# WBZ351 register map
Vendor: Microchip
Registers are 32-bit, read-write, reset 0x0 unless marked. A register's access mark holds for its fields unless they carry their own. Addresses are absolute, and some are shared; only a register's first bit layout is shown; [hi:lo] are bit positions; {n}, {i} and the like mark numbered series.

## EVSYS
0x41006000 CTRLA 8-bit
  [0] SWRST — Software Reset
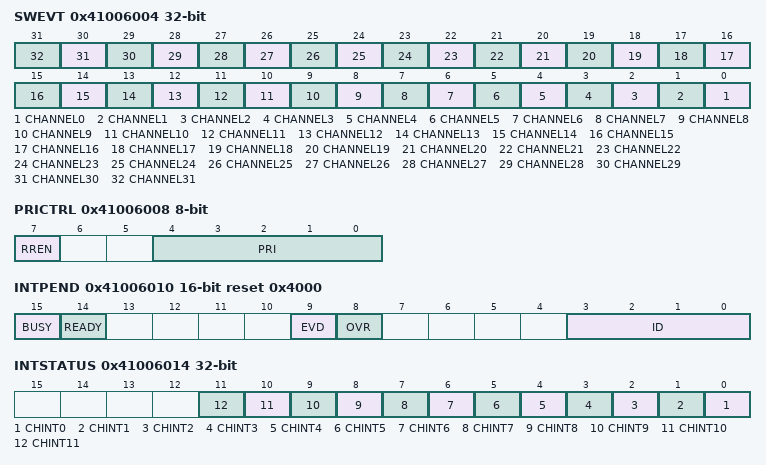
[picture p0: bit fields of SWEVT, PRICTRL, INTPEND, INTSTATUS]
0x41006004 SWEVT wo
  [n] CHANNEL{n} (n=0..31) — Channel {n} Software Selection
0x41006008 PRICTRL 8-bit
  [7] RREN — Round-Robin Scheduling Enable
  [4:0] PRI — Channel Priority Number
0x41006010 INTPEND 16-bit reset 0x4000
  [15] BUSY
  [14] READY
  [9] EVD — Channel Event Detected
  [8] OVR — Channel Overrun
  [3:0] ID — Channel ID
0x41006014 INTSTATUS ro
  [n] CHINT{n} (n=0..11) — Channel {n} Pending Interrupt
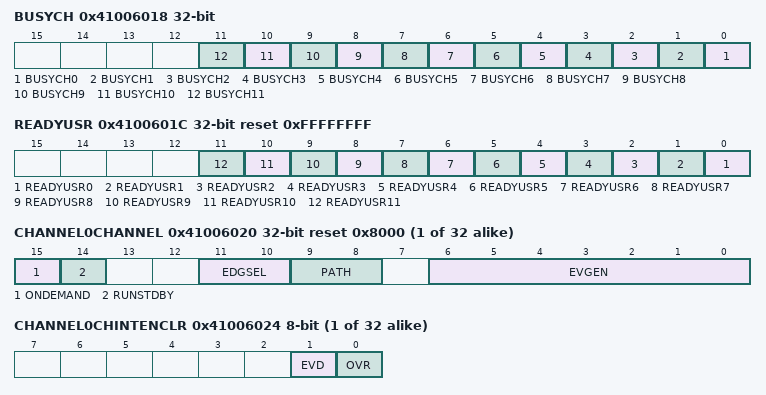
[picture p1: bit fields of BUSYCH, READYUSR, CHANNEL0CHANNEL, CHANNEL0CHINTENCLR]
0x41006018 BUSYCH ro
  [n] BUSYCH{n} (n=0..11) — Busy Channel {n}
0x4100601C READYUSR ro reset 0xFFFFFFFF
  [n] READYUSR{n} (n=0..11) — Ready User for Channel {n}
{0x41006020+8i} CHANNEL{i}CHANNEL reset 0x8000 (i=0..31)
  [15] ONDEMAND — Generic Clock On Demand
  [14] RUNSTDBY — Run in standby
  [11:10] EDGSEL — Edge Detection Selection
    0=NO_EVT_OUTPUT (No event output when using the resynchronized or synchronous path); 1=RISING_EDGE (Event detection only on the rising edge of the signal from the event generator when using the resynchronized or synchronous path); 2=FALLING_EDGE (Event detection only on the falling edge of the signal from the event generator when using the resynchronized or synchronous path); 3=BOTH_EDGES (Event detection on rising and falling edges of the signal from the event generator when using the resynchronized or synchronous path)
  [9:8] PATH — Path Selection
    0=SYNCHRONOUS (Synchronous path); 1=RESYNCHRONIZED (Resynchronized path); 2=ASYNCHRONOUS (Asynchronous path)
  [6:0] EVGEN — Event Generator Selection
{0x41006024+8i} CHANNEL{i}CHINTENCLR 8-bit (i=0..31)
  [1] EVD — Channel Event Detected Interrupt Disable
  [0] OVR — Channel Overrun Interrupt Disable
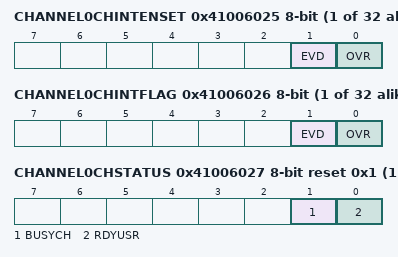
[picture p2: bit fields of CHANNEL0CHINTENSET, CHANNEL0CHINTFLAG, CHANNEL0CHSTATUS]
{0x41006025+8i} CHANNEL{i}CHINTENSET 8-bit (i=0..31)
  [1] EVD — Channel Event Detected Interrupt Enable
  [0] OVR — Channel Overrun Interrupt Enable
{0x41006026+8i} CHANNEL{i}CHINTFLAG 8-bit (i=0..31)
  [1] EVD — Channel Event Detected
  [0] OVR — Channel Overrun
{0x41006027+8i} CHANNEL{i}CHSTATUS 8-bit ro reset 0x1 (i=0..31)
  [1] BUSYCH — Busy Channel
  [0] RDYUSR — Ready User
{0x41006120+4i} USER{i} (i=0..56)
  [5:0] CHANNEL — Channel Event Selection

## RAMECC
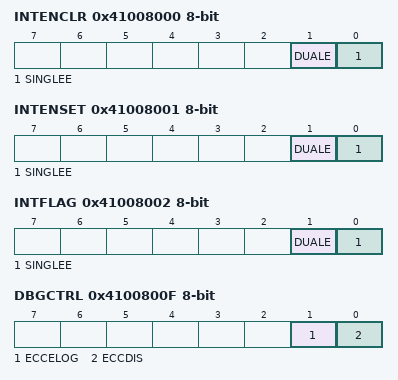
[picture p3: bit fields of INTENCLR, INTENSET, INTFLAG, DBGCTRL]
0x41008000 INTENCLR 8-bit
  [1] DUALE — Dual Bit ECC Error Interrupt Enable Clear
  [0] SINGLEE — Single Bit ECC Error Interrupt Enable Clear
0x41008001 INTENSET 8-bit
  [1] DUALE — Dual Bit ECC Error Interrupt Enable Set
  [0] SINGLEE — Single Bit ECC Error Interrupt Enable Set
0x41008002 INTFLAG 8-bit
  [1] DUALE — Dual Bit ECC Error Interrupt
  [0] SINGLEE — Single Bit ECC Error Interrupt
0x41008003 STATUS 8-bit ro
  [0] ECCDIS — ECC Disable
0x41008004 ERRADDR ro
  [17:0] ERRADDR — Error Address
0x4100800F DBGCTRL 8-bit
  [1] ECCELOG — ECC Error Log
  [0] ECCDIS — ECC Disable

## ARB
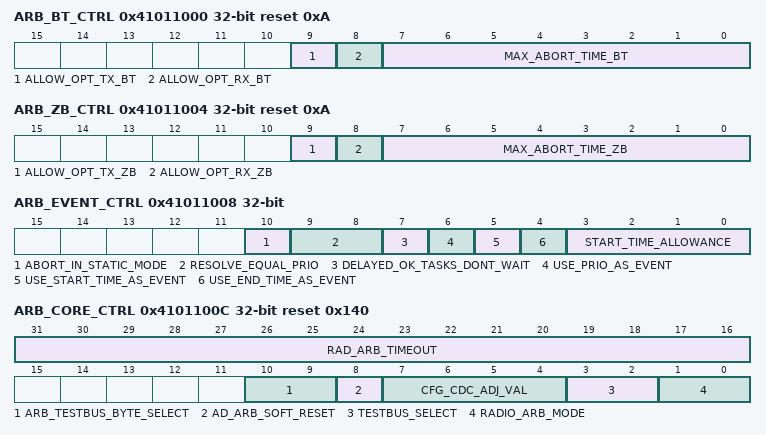
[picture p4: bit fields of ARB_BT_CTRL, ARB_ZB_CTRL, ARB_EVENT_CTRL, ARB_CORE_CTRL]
0x41011000 ARB_BT_CTRL reset 0xA
  [9] ALLOW_OPT_TX_BT — BT allow optimistic tx
  [8] ALLOW_OPT_RX_BT — BT allow optimistic rx
  [7:0] MAX_ABORT_TIME_BT — BT max abort time
0x41011004 ARB_ZB_CTRL reset 0xA
  [9] ALLOW_OPT_TX_ZB — ZB allow optimistic tx
  [8] ALLOW_OPT_RX_ZB — ZB allow optimistic rx
  [7:0] MAX_ABORT_TIME_ZB — ZB max abort time
0x41011008 ARB_EVENT_CTRL
  [10] ABORT_IN_STATIC_MODE
  [9:8] RESOLVE_EQUAL_PRIO
  [7] DELAYED_OK_TASKS_DONT_WAIT
  [6] USE_PRIO_AS_EVENT
  [5] USE_START_TIME_AS_EVENT
  [4] USE_END_TIME_AS_EVENT
  [3:0] START_TIME_ALLOWANCE — minimum change needed in the start time to be considered as an arbitration event.
0x4101100C ARB_CORE_CTRL reset 0x140
  [31:16] RAD_ARB_TIMEOUT, [10:9] ARB_TESTBUS_BYTE_SELECT, [8] AD_ARB_SOFT_RESET, [7:4] CFG_CDC_ADJ_VAL, [3:2] TESTBUS_SELECT, [1:0] RADIO_ARB_MODE
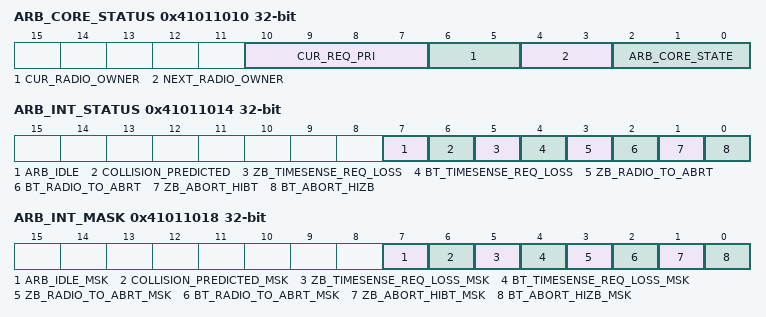
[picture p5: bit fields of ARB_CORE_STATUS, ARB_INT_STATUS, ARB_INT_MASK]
0x41011010 ARB_CORE_STATUS ro
  [10:7] CUR_REQ_PRI, [6:5] CUR_RADIO_OWNER, [4:3] NEXT_RADIO_OWNER, [2:0] ARB_CORE_STATE
0x41011014 ARB_INT_STATUS ro
  [7] ARB_IDLE, [6] COLLISION_PREDICTED, [5] ZB_TIMESENSE_REQ_LOSS, [4] BT_TIMESENSE_REQ_LOSS, [3] ZB_RADIO_TO_ABRT, [2] BT_RADIO_TO_ABRT, [1] ZB_ABORT_HIBT, [0] BT_ABORT_HIZB
0x41011018 ARB_INT_MASK
  [7] ARB_IDLE_MSK, [6] COLLISION_PREDICTED_MSK, [5] ZB_TIMESENSE_REQ_LOSS_MSK, [4] BT_TIMESENSE_REQ_LOSS_MSK, [3] ZB_RADIO_TO_ABRT_MSK, [2] BT_RADIO_TO_ABRT_MSK, [1] ZB_ABORT_HIBT_MSK, [0] BT_ABORT_HIZB_MSK
